AUTOSAR XML (schema 4-3-0)
package /ComponentTypes
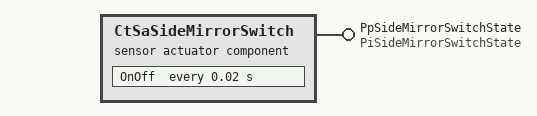
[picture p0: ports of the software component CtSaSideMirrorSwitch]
  sensor actuator sw component type CtSaSideMirrorSwitch
    provide port PpSideMirrorSwitchState: nonqueued-sender-com-spec{data-element=DeSideMirrorSelectionState, init-value=0}, provided-interface=PiSideMirrorSwitchState
    behavior CtSaSideMirrorSwitch_InternalBehavior
      timing event TMT_OnOff: start-on-event=OnOff, period=0.02
      runnable OnOff
        data-send-points:
          access SEND_PpSideMirrorSwitchState_DeSideMirrorSelectionState: accessed-variable=PpSideMirrorSwitchState.DeSideMirrorSelectionState
  swc implementation CtSaSideMirrorSwitch_Implementation: behavior=CtSaSideMirrorSwitch_InternalBehavior
